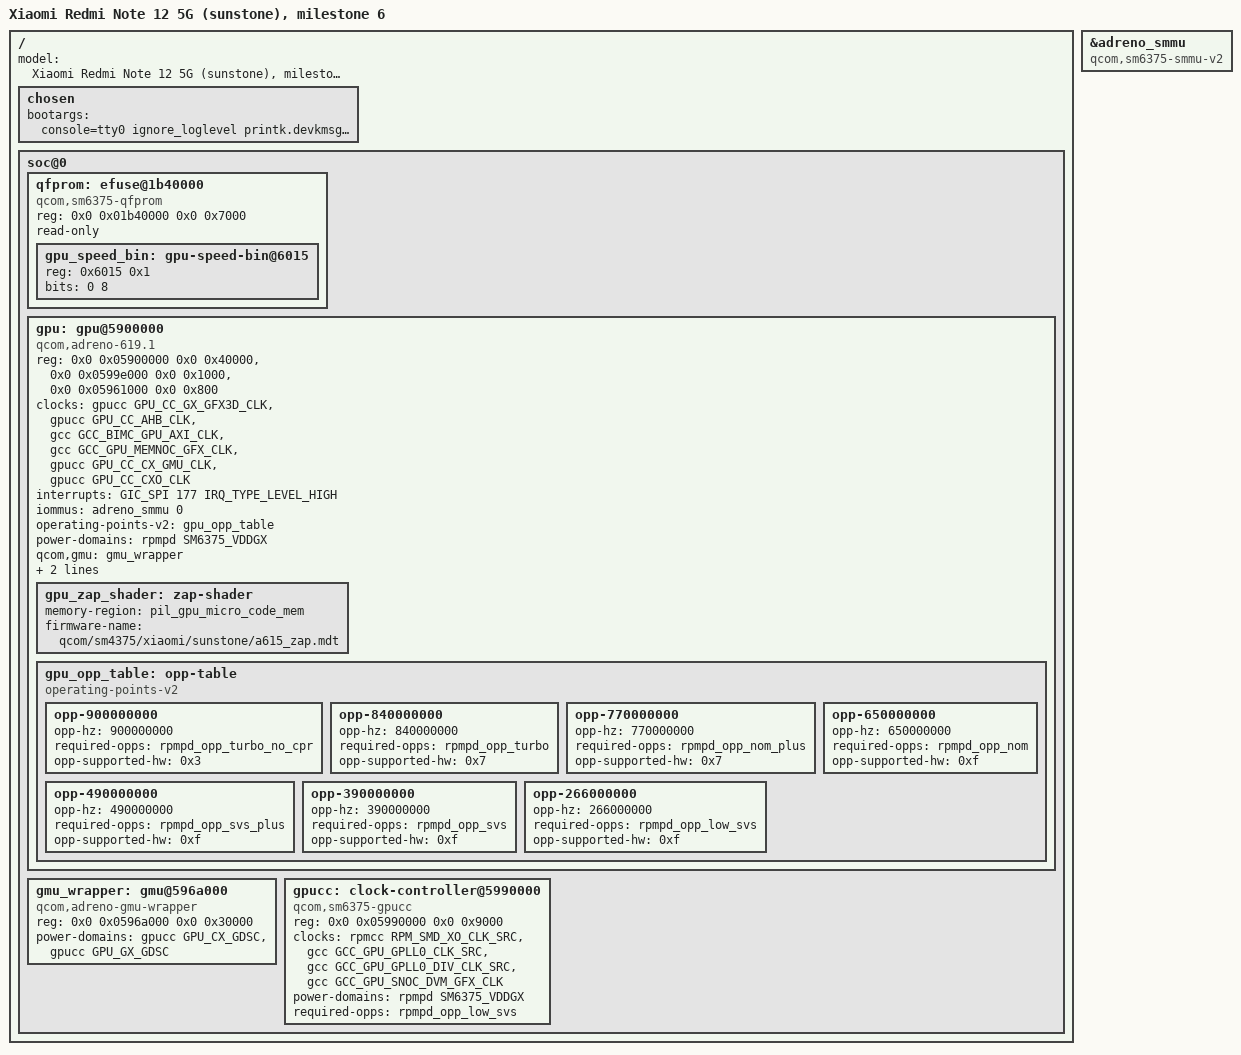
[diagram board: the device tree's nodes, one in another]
// SPDX-License-Identifier: BSD-3-Clause
/*
 * Xiaomi Redmi Note 12 5G (sunstone), SM4375 "blair": milestone 6 tree = M5 + the Adreno 619 GPU.
 *
 * sm6375.dtsi has no GPU nodes. This is mainline's a619_holi (chip id 0x06010901, GMU wrapper as on
 * sm6115's a610), with values from the downstream kgsl node: registers 0x5900000 / cx 0x599e000 /
 * dbgc 0x5961000, GMU wrapper 0x596a000, IRQ SPI 177, GX rail = RPM pm6125_s8 levels (rpmpd VDDGX).
 * Speed bins from the qfprom fuse at 0x6015 (downstream gpu_speed_bin): bins 0 and 190 run up to
 * 900 MHz, 177 up to 840 MHz, 148 (this phone) up to 700 MHz; 650 MHz and below are common to all. The zap shader is the
 * phone's own a615_zap (vendor partition, not in this repository).
 * The display is still ABL's splash on simpledrm, so the msm driver runs the GPU as a render-only
 * DRM device (msm.separate_gpu_kms=1).
 */
#include <dt-bindings/clock/qcom,sm6375-gpucc.h>
#include "sm4375-xiaomi-sunstone-m5.dts"

/ {
	model = "Xiaomi Redmi Note 12 5G (sunstone), milestone 6";

	chosen {
		bootargs = "console=tty0 ignore_loglevel printk.devkmsg=on panic=20 reboot=warm rdinit=/init clk_ignore_unused pd_ignore_unused msm.separate_gpu_kms=1";
	};

	soc@0 {
		qfprom: efuse@1b40000 {
			compatible = "qcom,sm6375-qfprom", "qcom,qfprom";
			reg = <0x0 0x01b40000 0x0 0x7000>;
			read-only;
			#address-cells = <1>;
			#size-cells = <1>;

			gpu_speed_bin: gpu-speed-bin@6015 {
				reg = <0x6015 0x1>;
				bits = <0 8>;
			};
		};

		gpu: gpu@5900000 {
			compatible = "qcom,adreno-619.1", "qcom,adreno";
			reg = <0x0 0x05900000 0x0 0x40000>,
			      <0x0 0x0599e000 0x0 0x1000>,
			      <0x0 0x05961000 0x0 0x800>;
			reg-names = "kgsl_3d0_reg_memory",
				    "cx_mem",
				    "cx_dbgc";

			/* no (real) GMU: the GPU driver handles the clocks itself */
			clocks = <&gpucc GPU_CC_GX_GFX3D_CLK>,
				 <&gpucc GPU_CC_AHB_CLK>,
				 <&gcc GCC_BIMC_GPU_AXI_CLK>,
				 <&gcc GCC_GPU_MEMNOC_GFX_CLK>,
				 <&gpucc GPU_CC_CX_GMU_CLK>,
				 <&gpucc GPU_CC_CXO_CLK>;
			clock-names = "core",
				      "iface",
				      "mem_iface",
				      "alt_mem_iface",
				      "gmu",
				      "xo";

			interrupts = <GIC_SPI 177 IRQ_TYPE_LEVEL_HIGH>;

			iommus = <&adreno_smmu 0>;
			operating-points-v2 = <&gpu_opp_table>;
			power-domains = <&rpmpd SM6375_VDDGX>;
			qcom,gmu = <&gmu_wrapper>;

			nvmem-cells = <&gpu_speed_bin>;
			nvmem-cell-names = "speed_bin";
			#cooling-cells = <2>;

			gpu_zap_shader: zap-shader {
				memory-region = <&pil_gpu_micro_code_mem>;
				firmware-name = "qcom/sm4375/xiaomi/sunstone/a615_zap.mdt";
			};

			/*
			 * opp-supported-hw: BIT(n) for the catalog's speed bins {0: 0, 190: 1, 177: 2, 148: 3}
			 * (148 from kernel/patches/0007; sunstone is a bin-148 part, downstream max 700 MHz,
			 * which gpucc cannot make: 650 MHz is its top here)
			 */
			gpu_opp_table: opp-table {
				compatible = "operating-points-v2";

				opp-900000000 {
					opp-hz = /bits/ 64 <900000000>;
					required-opps = <&rpmpd_opp_turbo_no_cpr>;
					opp-supported-hw = <0x3>;
				};

				opp-840000000 {
					opp-hz = /bits/ 64 <840000000>;
					required-opps = <&rpmpd_opp_turbo>;
					opp-supported-hw = <0x7>;
				};

				opp-770000000 {
					opp-hz = /bits/ 64 <770000000>;
					required-opps = <&rpmpd_opp_nom_plus>;
					opp-supported-hw = <0x7>;
				};

				opp-650000000 {
					opp-hz = /bits/ 64 <650000000>;
					required-opps = <&rpmpd_opp_nom>;
					opp-supported-hw = <0xf>;
				};

				opp-490000000 {
					opp-hz = /bits/ 64 <490000000>;
					required-opps = <&rpmpd_opp_svs_plus>;
					opp-supported-hw = <0xf>;
				};

				opp-390000000 {
					opp-hz = /bits/ 64 <390000000>;
					required-opps = <&rpmpd_opp_svs>;
					opp-supported-hw = <0xf>;
				};

				opp-266000000 {
					opp-hz = /bits/ 64 <266000000>;
					required-opps = <&rpmpd_opp_low_svs>;
					opp-supported-hw = <0xf>;
				};
			};
		};

		gmu_wrapper: gmu@596a000 {
			compatible = "qcom,adreno-gmu-wrapper";
			reg = <0x0 0x0596a000 0x0 0x30000>;
			reg-names = "gmu";
			power-domains = <&gpucc GPU_CX_GDSC>,
					<&gpucc GPU_GX_GDSC>;
			power-domain-names = "cx", "gx";
		};

		gpucc: clock-controller@5990000 {
			compatible = "qcom,sm6375-gpucc";
			reg = <0x0 0x05990000 0x0 0x9000>;
			clocks = <&rpmcc RPM_SMD_XO_CLK_SRC>,
				 <&gcc GCC_GPU_GPLL0_CLK_SRC>,
				 <&gcc GCC_GPU_GPLL0_DIV_CLK_SRC>,
				 <&gcc GCC_GPU_SNOC_DVM_GFX_CLK>;
			power-domains = <&rpmpd SM6375_VDDGX>;
			required-opps = <&rpmpd_opp_low_svs>;
			#clock-cells = <1>;
			#reset-cells = <1>;
			#power-domain-cells = <1>;
		};
	};
};

/*
 * sm6375.dtsi leaves "qcom,adreno-smmu" out of the GPU SMMU: without it arm-smmu-qcom does not use
 * its Adreno implementation and msm gets no per-process page tables ("No per-process page tables").
 */
&adreno_smmu {
	compatible = "qcom,sm6375-smmu-v2", "qcom,adreno-smmu", "qcom,smmu-v2";
};
